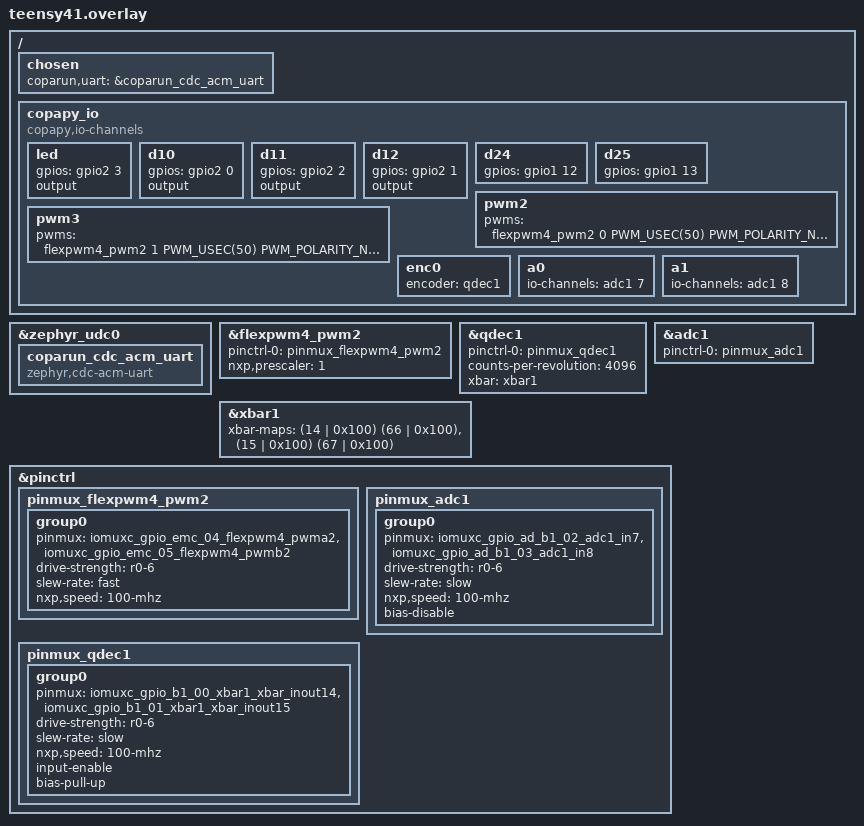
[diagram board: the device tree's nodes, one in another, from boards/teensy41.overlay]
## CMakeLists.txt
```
cmake_minimum_required(VERSION 3.20.0)

find_package(Zephyr REQUIRED HINTS $ENV{ZEPHYR_BASE})
project(coparun)

# Core of the runner, shared with the other runners
set(CORE_DIR ${CMAKE_CURRENT_SOURCE_DIR}/../../src/coparun)

target_sources(app PRIVATE
    src/main.c
    src/tasks.c
    src/io.c
    ${CORE_DIR}/runmem.c
    ${CORE_DIR}/tasks.c
    ${CORE_DIR}/mem_man.c
)
target_include_directories(app PRIVATE ${CORE_DIR})

if(CONFIG_COPARUN_LOGGING)
    target_compile_definitions(app PRIVATE ENABLE_LOGGING)
else()
    target_compile_definitions(app PRIVATE ENABLE_BASIC_LOGGING)
endif()
```

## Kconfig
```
menu "coparun"

config COPARUN_HEAP_SIZE
	int "Size of the heap for copapy programs in bytes"
	default 262144
	help
	  The heap holds the code and data memory of the copapy programs.

config COPARUN_HEAP_SECTION
	string "Linker section of the heap for copapy programs"
	default ".noinit.coparun_heap"
	help
	  Code is executed from the heap, it must be located in memory that is
	  not marked execute-never by the MPU. With CONFIG_ARM_MPU the main RAM
	  is execute-never on targets running from flash: either select the
	  section of a memory region that is not covered by an MPU region (name
	  of a devicetree node with zephyr,memory-region) or disable the MPU.

config COPARUN_MAX_FRAME_SIZE
	int "Maximum size of the command stream part of a frame in bytes"
	default 4096

config COPARUN_RX_RING_SIZE
	int "Size of the UART receive ring buffer in bytes"
	default 2048

config COPARUN_TX_RING_SIZE
	int "Size of the UART transmit ring buffer in bytes"
	default 1024

config COPARUN_TX_TIMEOUT_MS
	int "Time without progress after which output is dropped in ms"
	default 500
	help
	  Output is written blocking. If the host does not read it for this
	  time, the output is dropped until the host reads again.

config COPARUN_RX_TIMEOUT_MS
	int "Timeout for receiving the remaining bytes of a frame in ms"
	default 2000

config COPARUN_MAX_TASKS
	int "Maximum number of tasks for the real-time execution"
	default 8
	range 1 32

config COPARUN_TASK_PRIORITY
	int "Thread priority of the first (highest priority) task"
	default 1
	help
	  Task n runs with this priority + n. The main thread must have a
	  lower priority (higher number) than all tasks.

config COPARUN_MAX_TASK_LOAD
	int "Maximum CPU load of the tasks in percent"
	default 90
	range 10 100
	help
	  If the tasks use more CPU time, the tasks with the lowest priority
	  run with lower priority than the communication with the host until
	  the load is below the limit again (load shedding, see tasks.c).
	  100 disables the load shedding.

config COPARUN_LOAD_WINDOW_MS
	int "Time window of the load measurement in ms"
	default 100

config COPARUN_TASK_STACK_SIZE
	int "Stack size of each task thread in bytes"
	default 2048

config COPARUN_LOGGING
	bool "Log all commands of the command stream"
	help
	  Without this option only the return value of the program and the
	  data of READ_DATA commands are written to the console.

endmenu

source "Kconfig.zephyr"

# mps2/an500 is used for testing in qemu: its Cortex-M7 has an FPU, which is
# not declared by the SoC definition of Zephyr
config SOC_AN500
	select CPU_HAS_FPU
```

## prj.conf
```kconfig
# The stencils use the FPU with the hard float ABI
CONFIG_FPU=y
CONFIG_FPU_SHARING=y
CONFIG_FP_HARDABI=y

# Command streams are received over the console UART
CONFIG_SERIAL=y
CONFIG_UART_INTERRUPT_DRIVEN=y
CONFIG_RING_BUFFER=y
CONFIG_CRC=y
CONFIG_REBOOT=y

# Device I/O channels (io.c)
CONFIG_GPIO=y

# Programs run on the main thread (RUN_PROG, RUN_TASK, STEP_TASKS) and
# periodic tasks on threads with higher priority than the main thread
CONFIG_MAIN_STACK_SIZE=8192
CONFIG_MAIN_THREAD_PRIORITY=10
# Priorities below the main thread for degraded tasks (load shedding)
CONFIG_NUM_PREEMPT_PRIORITIES=24

# Tick of the periodic tasks: 100 us
CONFIG_SYS_CLOCK_TICKS_PER_SEC=10000

# CPU time of the task threads for the execution time measurement
CONFIG_THREAD_RUNTIME_STATS=y
```

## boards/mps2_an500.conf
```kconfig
# The heap is located in the main RAM, which is execute-never with MPU
CONFIG_ARM_MPU=n

CONFIG_COPARUN_HEAP_SIZE=1048576
```

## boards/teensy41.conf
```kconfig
# The MPU stays enabled (required by the USB driver). The main RAM (FlexRAM
# OCRAM, 256 KiB) is execute-never, the heap uses the complete 512 KiB OCRAM2
# instead, which is not covered by an MPU region.
CONFIG_COPARUN_HEAP_SECTION="OCRAM2"
CONFIG_COPARUN_HEAP_SIZE=524288

# Drivers of the I/O channels (see teensy41.overlay), the quadrature decoder
# is a sensor driver
CONFIG_PWM=y
CONFIG_SENSOR=y
CONFIG_ADC=y

# USB serial port of the runner
CONFIG_USB_DEVICE_STACK_NEXT=y
CONFIG_CDC_ACM_SERIAL_INITIALIZE_AT_BOOT=y

# USB processing must not delay the tasks: preemptible work queues with
# lower priority than the task threads (the default is cooperative)
CONFIG_UDC_WORKQUEUE_PRIORITY=9
CONFIG_SYSTEM_WORKQUEUE_PRIORITY=9
```

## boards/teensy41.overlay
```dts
/*
 * The runner communicates over USB (CDC ACM), the Zephyr console stays on
 * LPUART6 (Teensy pins 0 and 1).
 */

#include <zephyr/dt-bindings/gpio/gpio.h>
#include <zephyr/dt-bindings/pwm/pwm.h>

/ {
	chosen {
		coparun,uart = &coparun_cdc_acm_uart;
	};

	/* I/O channels for copapy (see dts/bindings/copapy,io-channels.yaml),
	 * named by Teensy pin numbers. Pins 0/1 are the console, 22/23 CAN. */
	copapy_io {
		compatible = "copapy,io-channels";

		led {
			gpios = <&gpio2 3 GPIO_ACTIVE_HIGH>;    /* pin 13, GPIO_B0_03 */
			output;
		};
		d10 {
			gpios = <&gpio2 0 GPIO_ACTIVE_HIGH>;    /* GPIO_B0_00 */
			output;
		};
		d11 {
			gpios = <&gpio2 2 GPIO_ACTIVE_HIGH>;    /* GPIO_B0_02 */
			output;
		};
		d12 {
			gpios = <&gpio2 1 GPIO_ACTIVE_HIGH>;    /* GPIO_B0_01 */
			output;
		};
		d24 {
			gpios = <&gpio1 12 (GPIO_ACTIVE_HIGH | GPIO_PULL_UP)>;  /* GPIO_AD_B0_12 */
		};
		d25 {
			gpios = <&gpio1 13 (GPIO_ACTIVE_HIGH | GPIO_PULL_UP)>;  /* GPIO_AD_B0_13 */
		};
		pwm2 {
			pwms = <&flexpwm4_pwm2 0 PWM_USEC(50) PWM_POLARITY_NORMAL>;  /* 20 kHz */
		};
		pwm3 {
			pwms = <&flexpwm4_pwm2 1 PWM_USEC(50) PWM_POLARITY_NORMAL>;
		};
		enc0 {
			encoder = <&qdec1>;                      /* phase A pin 8, B pin 7 */
		};
		a0 {
			io-channels = <&adc1 7>;                 /* pin 14 */
		};
		a1 {
			io-channels = <&adc1 8>;                 /* pin 15 */
		};
	};
};

&zephyr_udc0 {
	coparun_cdc_acm_uart: coparun_cdc_acm_uart {
		compatible = "zephyr,cdc-acm-uart";
	};
};

/* PWM pins 2 (A) and 3 (B): FlexPWM4 submodule 2 at full clock (150 MHz,
 * 7500 steps at 20 kHz) */
&flexpwm4_pwm2 {
	status = "okay";
	pinctrl-0 = <&pinmux_flexpwm4_pwm2>;
	pinctrl-names = "default";
	nxp,prescaler = <1>;
};

/* Quadrature decoder ENC1, inputs through the crossbar */
&qdec1 {
	status = "okay";
	pinctrl-0 = <&pinmux_qdec1>;
	pinctrl-names = "default";
	counts-per-revolution = <4096>;
	xbar = <&xbar1>;
};

&xbar1 {
	status = "okay";
	xbar-maps =
		/* kXBARA1_InputIomuxXbarInout14 -> kXBARA1_OutputEnc1PhaseAInput */
		<(14 | 0x100) (66 | 0x100)>,
		/* kXBARA1_InputIomuxXbarInout15 -> kXBARA1_OutputEnc1PhaseBInput */
		<(15 | 0x100) (67 | 0x100)>;
};

/* ADC1, its driver requires a pin configuration */
&adc1 {
	status = "okay";
	pinctrl-0 = <&pinmux_adc1>;
	pinctrl-names = "default";
};

&pinctrl {
	pinmux_flexpwm4_pwm2: pinmux_flexpwm4_pwm2 {
		group0 {
			pinmux = <&iomuxc_gpio_emc_04_flexpwm4_pwma2>,
				 <&iomuxc_gpio_emc_05_flexpwm4_pwmb2>;
			drive-strength = "r0-6";
			slew-rate = "fast";
			nxp,speed = "100-mhz";
		};
	};

	pinmux_adc1: pinmux_adc1 {
		group0 {
			pinmux = <&iomuxc_gpio_ad_b1_02_adc1_in7>,
				 <&iomuxc_gpio_ad_b1_03_adc1_in8>;
			drive-strength = "r0-6";
			slew-rate = "slow";
			nxp,speed = "100-mhz";
			bias-disable;
		};
	};

	pinmux_qdec1: pinmux_qdec1 {
		group0 {
			pinmux = <&iomuxc_gpio_b1_00_xbar1_xbar_inout14>,
				 <&iomuxc_gpio_b1_01_xbar1_xbar_inout15>;
			drive-strength = "r0-6";
			slew-rate = "slow";
			nxp,speed = "100-mhz";
			input-enable;
			bias-pull-up;
		};
	};
};
```

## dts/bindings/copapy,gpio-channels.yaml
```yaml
description: |
  GPIO channels of the copapy runner. Each child node is a channel, named by
  the node name (e.g. "led"). Copapy values are bound to the channels by name
  with SerialTarget.bind.

    copapy_gpio {
        compatible = "copapy,gpio-channels";
        led {
            gpios = <&gpio2 3 GPIO_ACTIVE_HIGH>;
            output;
        };
        button {
            gpios = <&gpio1 12 (GPIO_ACTIVE_LOW | GPIO_PULL_UP)>;
        };
    };

compatible: "copapy,gpio-channels"

child-binding:
  description: GPIO channel
  properties:
    gpios:
      type: phandle-array
      required: true
      description: Pin, active level and pull resistor of the channel
    output:
      type: boolean
      description: Output channel, otherwise input channel
```

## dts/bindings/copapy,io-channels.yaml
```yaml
description: |
  I/O channels of the copapy runner. Each child node is a channel, named by
  the node name. Copapy values are bound to the channels by name with
  SerialTarget.bind. The kind of a channel follows from its property:

    copapy_io {
        compatible = "copapy,io-channels";
        led {
            gpios = <&gpio2 3 GPIO_ACTIVE_HIGH>;
            output;
        };
        motor {
            pwms = <&flexpwm4_pwm2 0 PWM_USEC(50) PWM_POLARITY_NORMAL>;
        };
        enc0 {
            encoder = <&qdec1>;
        };
        a0 {
            io-channels = <&adc1 7>;
        };
    };

compatible: "copapy,io-channels"

child-binding:
  description: I/O channel
  properties:
    gpios:
      type: phandle-array
      description: GPIO pin, active level and pull resistor
    output:
      type: boolean
      description: GPIO output, otherwise GPIO input
    pwms:
      type: phandle-array
      description: PWM output with period and polarity, the duty cycle is written
    encoder:
      type: phandle
      description: Quadrature decoder, the position count is read
    io-channels:
      type: phandle-array
      description: ADC and its input, the raw conversion result is read
```

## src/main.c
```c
/*
 * file: main.c
 * Description: Runner for Zephyr targets. Command streams are received
 * framed over a UART, the output of the runner is sent in binary messages
 * (protocol.h) over the same UART. The UART is selected by the chosen
 * devicetree node "coparun,uart" (e.g. a USB CDC ACM device), by default it
 * is the console. The protocol is described in docs/source/runner_transfer.md.
 *
 * Stream frame (integers little endian):
 *   4 bytes  magic "CPY1"
 *   uint32   length n of the following part of the command stream in bytes,
 *            at most CONFIG_COPARUN_MAX_FRAME_SIZE
 *   n bytes  part of the command stream
 *   uint32   CRC-32 (IEEE 802.3, as zlib.crc32) of the n bytes
 *
 * A command stream can be split at any position into several frames. Each
 * frame is answered with the output of the runner followed by a MSG_DONE
 * message with the state flag of the parser (0: command stream is continued
 * by the next frame, 1: END_COM reached, 2: DUMP_CODE reached, negative:
 * error), or by MSG_ERROR if the frame was not valid. A frame is processed
 * only after its checksum was verified, a frame answered with ERR_TIMEOUT or
 * ERR_CHECKSUM can be sent again. The next frame must not be sent before the
 * answer was received. The run-time memory state is kept between frames and
 * command streams.
 *
 * Control frame:
 *   4 bytes  magic "CPYC"
 *   uint32   0: abort the current command stream, the next frame starts a
 *               new one
 *            1: reset the device
 *            2: enter the bootloader, Teensy only
 *            answered by MSG_CONTROL with the code before it is executed
 *
 * Bytes in front of a magic are ignored. After start up MSG_READY is sent.
 * Text written to stdout is sent in MSG_TEXT messages, the data of READ_MEM
 * in MSG_DATA messages.
 *
 * Periodic tasks are run in real time after START_TASKS (see tasks.c), the
 * communication with the host continues meanwhile.
 */

#include <stdio.h>
#include <stdint.h>
#include <string.h>
#include <zephyr/kernel.h>
#include <zephyr/device.h>
#include <zephyr/drivers/uart.h>
#include <zephyr/sys/byteorder.h>
#include <zephyr/sys/crc.h>
#include <zephyr/sys/libc-hooks.h>
#include <zephyr/sys/printk.h>
#include <zephyr/sys/reboot.h>
#include <zephyr/sys/ring_buffer.h>
#include "runmem.h"
#include "tasks.h"
#include "protocol.h"

#define RX_TIMEOUT K_MSEC(CONFIG_COPARUN_RX_TIMEOUT_MS)

/* UART of the runner: chosen node "coparun,uart", by default the console */
#if DT_HAS_CHOSEN(coparun_uart)
#define COPARUN_UART_NODE DT_CHOSEN(coparun_uart)
#else
#define COPARUN_UART_NODE DT_CHOSEN(zephyr_console)
#endif

static const struct device *const uart_dev = DEVICE_DT_GET(COPARUN_UART_NODE);

static const uint8_t frame_magic[3] = {'C', 'P', 'Y'};
#define FRAME_TYPE_STREAM  '1'
#define FRAME_TYPE_CONTROL 'C'

#define CONTROL_ABORT      0
#define CONTROL_RESET      1
#define CONTROL_BOOTLOADER 2

RING_BUF_DECLARE(rx_ring, CONFIG_COPARUN_RX_RING_SIZE);
static K_SEM_DEFINE(rx_sem, 0, 1);
static volatile bool rx_paused;

RING_BUF_DECLARE(tx_ring, CONFIG_COPARUN_TX_RING_SIZE);
static K_SEM_DEFINE(tx_sem, 0, 1);
static volatile bool tx_stalled;

/* Command stream of a frame, preceded by the bytes of an incomplete command
   of the previous frame (at most 19 bytes) */
#define MAX_PENDING 20
static uint8_t frame_buffer[MAX_PENDING + CONFIG_COPARUN_MAX_FRAME_SIZE];
static uint32_t pending;

/* Text output, sent at the end of a line, if the buffer is full or before
   the next message */
static uint8_t text_buffer[MSG_MAX_PAYLOAD];
static uint32_t text_len;

static runmem_t targ;

static void uart_isr(const struct device *dev, void *user_data) {
    ARG_UNUSED(user_data);

    while (uart_irq_update(dev) && uart_irq_is_pending(dev)) {
        if (uart_irq_rx_ready(dev)) {
            uint8_t *data;
            uint32_t space = ring_buf_put_claim(&rx_ring, &data, CONFIG_COPARUN_RX_RING_SIZE);

            if (space) {
                int len = uart_fifo_read(dev, data, (int)space);

                ring_buf_put_finish(&rx_ring, len > 0 ? (uint32_t)len : 0);
            } else {
                /* Receiving is paused until the main thread has read data:
                   back pressure to the host if the driver supports it (USB) */
                uart_irq_rx_disable(dev);
                rx_paused = true;
            }
            k_sem_give(&rx_sem);
        }
        if (uart_irq_tx_ready(dev)) {
            uint8_t *data;
            uint32_t len = ring_buf_get_claim(&tx_ring, &data, CONFIG_COPARUN_TX_RING_SIZE);

            if (len) {
                int sent = uart_fifo_fill(dev, data, (int)len);

                ring_buf_get_finish(&tx_ring, sent > 0 ? (uint32_t)sent : 0);
                tx_stalled = false;
            } else {
                uart_irq_tx_disable(dev);
            }
            k_sem_give(&tx_sem);
        }
    }
}

/* Output: written without loss as long as the host reads it. The poll mode
   of a USB CDC ACM device drops characters if its buffer is full. */
static void tx_put(const uint8_t *data, uint32_t len) {
    while (len) {
        uint32_t n = ring_buf_put(&tx_ring, data, len);

        data += n;
        len -= n;
        if (!len) break;
        /* Output is dropped if the host does not read it */
        if (tx_stalled) return;
        uart_irq_tx_enable(uart_dev);
        if (k_sem_take(&tx_sem, K_MSEC(CONFIG_COPARUN_TX_TIMEOUT_MS)) != 0) {
            tx_stalled = true;
            return;
        }
    }
}

static void put_message(uint8_t type, const void *payload, uint32_t len) {
    uint8_t header[4] = {MSG_SYNC, type, (uint8_t)len, (uint8_t)(type ^ len ^ 0xFF)};
    uint8_t crc[2];

    sys_put_le16(crc16_itu_t(crc16_itu_t(0, header + 1, 3), payload, len), crc);
    tx_put(header, sizeof(header));
    tx_put(payload, len);
    tx_put(crc, sizeof(crc));
    uart_irq_tx_enable(uart_dev);
}

static void text_flush(void) {
    if (text_len) {
        put_message(MSG_TEXT, text_buffer, text_len);
        text_len = 0;
    }
}

void send_message(uint8_t type, const void *payload, uint32_t len) {
    text_flush();
    put_message(type, payload, len);
}

static void send_byte(uint8_t type, uint8_t value) {
    send_message(type, &value, 1);
}

static int stdout_write(int c) {
    text_buffer[text_len++] = (uint8_t)c;
    if (c == '\n' || text_len == sizeof(text_buffer)) text_flush();
    return c;
}

void runmem_write_data(const uint8_t *data, uint32_t size) {
    while (size) {
        uint32_t len = size < MSG_MAX_PAYLOAD ? size : MSG_MAX_PAYLOAD;

        send_message(MSG_DATA, data, len);
        data += len;
        size -= len;
    }
}

/* Reads len bytes, returns 0 if no data was received for the time of timeout */
static int read_bytes(uint8_t *dest, uint32_t len, k_timeout_t timeout) {
    while (len) {
        uint32_t n = ring_buf_get(&rx_ring, dest, len);

        dest += n;
        len -= n;
        if (rx_paused) {
            /* Space in the ring buffer again */
            rx_paused = false;
            uart_irq_rx_enable(uart_dev);
        }
        if (!n && k_sem_take(&rx_sem, timeout) != 0) return 0;
    }
    return 1;
}

/* Waits for the magic of a frame, returns its last character (frame type) */
static uint8_t wait_for_magic(void) {
    uint32_t matched = 0;
    uint8_t c;

    for (;;) {
        read_bytes(&c, 1, K_FOREVER);
        if (matched == sizeof(frame_magic)) {
            if (c == FRAME_TYPE_STREAM || c == FRAME_TYPE_CONTROL) return c;
            matched = 0;
        }
        if (c == frame_magic[matched]) {
            matched++;
        } else {
            matched = (c == frame_magic[0]);
        }
    }
}

/* Receives the remaining stream frame after the magic and appends the
   command stream to frame_buffer, returns ERR_* on failure, else 0 */
static uint8_t receive_frame(uint32_t *len) {
    uint8_t word[4];

    if (!read_bytes(word, sizeof(word), RX_TIMEOUT)) return ERR_TIMEOUT;
    *len = sys_get_le32(word);

    if (*len > CONFIG_COPARUN_MAX_FRAME_SIZE) return ERR_FRAME_TOO_LARGE;
    if (!read_bytes(frame_buffer + pending, *len, RX_TIMEOUT) ||
        !read_bytes(word, sizeof(word), RX_TIMEOUT)) return ERR_TIMEOUT;
    if (sys_get_le32(word) != crc32_ieee(frame_buffer + pending, *len)) return ERR_CHECKSUM;
    return 0;
}

static void process_stream_frame(void) {
    uint32_t len;
    uint8_t error = receive_frame(&len);

    if (error) {
        send_byte(MSG_ERROR, error);
        return;
    }

    uint32_t consumed = (uint32_t)parse_commands(&targ, frame_buffer, pending + len);

    if (targ.state_flag == STATE_FLAG_NONE) {
        /* Keep the bytes of an incomplete command for the next frame */
        pending += len - consumed;
        memmove(frame_buffer, frame_buffer + consumed, pending);
    } else {
        /* End of the command stream or parser out of sync */
        pending = 0;
        targ.rx_state = RX_STATE_IDLE;
    }
    fflush(stdout);
    send_byte(MSG_DONE, (uint8_t)(int8_t)targ.state_flag);
}

static void process_control_frame(void) {
    uint8_t word[4];

    if (!read_bytes(word, sizeof(word), RX_TIMEOUT)) {
        send_byte(MSG_ERROR, ERR_TIMEOUT);
        return;
    }

    switch (sys_get_le32(word)) {
        case CONTROL_ABORT:
            pending = 0;
            targ.rx_state = RX_STATE_IDLE;
            send_byte(MSG_CONTROL, CONTROL_ABORT);
            break;

        case CONTROL_RESET:
            send_byte(MSG_CONTROL, CONTROL_RESET);
            k_msleep(100);  /* Let the output drain */
            sys_reboot(SYS_REBOOT_COLD);
            break;

#ifdef CONFIG_BOARD_TEENSY41
        case CONTROL_BOOTLOADER:
            send_byte(MSG_CONTROL, CONTROL_BOOTLOADER);
            k_msleep(100);
            /* Request of the bootloader chip of the Teensy (HalfKay) */
            __asm__ volatile("bkpt #251");
            break;
#endif

        default:
            send_byte(MSG_ERROR, ERR_CONTROL_CODE);
            break;
    }
}

int main(void) {
    if (!device_is_ready(uart_dev)) {
        printk("coparun: UART not ready\n");
        return 0;
    }

    uart_irq_callback_set(uart_dev, uart_isr);
    uart_irq_rx_enable(uart_dev);
    __stdout_hook_install(stdout_write);

    send_byte(MSG_READY, PROTOCOL_VERSION);

    for (;;) {
        if (wait_for_magic() == FRAME_TYPE_STREAM) {
            process_stream_frame();
        } else {
            process_control_frame();
        }
    }
    return 0;
}
```

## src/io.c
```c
/*
 * file: io.c
 * Description: Device I/O channels of the runner. The channels are child
 * nodes of the devicetree node "copapy,io-channels" (see
 * dts/bindings/copapy,io-channels.yaml), numbered in the order of
 * definition. The kind of a channel follows from its property:
 *   gpios        gpio_in / gpio_out  int32, 0: inactive, else active
 *   pwms         pwm_out             float, duty cycle 0..1
 *   encoder      encoder_in          int32, position count
 *   io-channels  adc_in              int32, raw conversion result
 *
 * Channels are read and written in the interrupt of the task tick (see
 * runmem.h). The Zephyr drivers initialize the peripherals, PWM, encoder
 * and ADC are accessed by registers since their driver functions block.
 */

#include <stdio.h>
#include <string.h>
#include <zephyr/kernel.h>
#include <zephyr/init.h>
#include <zephyr/drivers/gpio.h>
#include <zephyr/drivers/pwm.h>
#include <zephyr/sys/byteorder.h>
#include "runmem.h"
#include "tasks.h"
#include "protocol.h"

enum kind {
    GPIO_IN = IO_KIND_GPIO_IN,
    GPIO_OUT = IO_KIND_GPIO_OUT,
    PWM_OUT = IO_KIND_PWM_OUT,
    ENCODER_IN = IO_KIND_ENCODER_IN,
    ADC_IN = IO_KIND_ADC_IN
};

struct channel {
    const char *name;
    enum kind kind;
    struct gpio_dt_spec gpio;    /* GPIO */
    struct pwm_dt_spec pwm;      /* PWM */
    const struct device *dev;    /* encoder, ADC */
    uintptr_t base;              /* registers of the PWM, encoder or ADC */
    uint32_t index;              /* PWM submodule, ADC input */
};

#define IO_NODE DT_COMPAT_GET_ANY_STATUS_OKAY(copapy_io_channels)

#define GPIO_CHANNEL(node) \
    .kind = DT_PROP(node, output) ? GPIO_OUT : GPIO_IN, \
    .gpio = GPIO_DT_SPEC_GET(node, gpios),

#define PWM_CHANNEL(node) \
    .kind = PWM_OUT, \
    .pwm = PWM_DT_SPEC_GET(node), \
    .base = DT_REG_ADDR(DT_PARENT(DT_PWMS_CTLR(node))), \
    .index = DT_PROP(DT_PWMS_CTLR(node), index),

#define ENCODER_CHANNEL(node) \
    .kind = ENCODER_IN, \
    .dev = DEVICE_DT_GET(DT_PHANDLE(node, encoder)), \
    .base = DT_REG_ADDR(DT_PHANDLE(node, encoder)),

#define ADC_CHANNEL(node) \
    .kind = ADC_IN, \
    .dev = DEVICE_DT_GET(DT_IO_CHANNELS_CTLR(node)), \
    .base = DT_REG_ADDR(DT_IO_CHANNELS_CTLR(node)), \
    .index = DT_IO_CHANNELS_INPUT(node),

#define CHANNEL(node) {                                                     \
    .name = DT_NODE_FULL_NAME(node),                                        \
    COND_CODE_1(DT_NODE_HAS_PROP(node, gpios), (GPIO_CHANNEL(node)),        \
    (COND_CODE_1(DT_NODE_HAS_PROP(node, pwms), (PWM_CHANNEL(node)),         \
    (COND_CODE_1(DT_NODE_HAS_PROP(node, encoder), (ENCODER_CHANNEL(node)),  \
    (ADC_CHANNEL(node)))))))                                                \
},

#if DT_NODE_EXISTS(IO_NODE)
static const struct channel channels[] = {DT_FOREACH_CHILD(IO_NODE, CHANNEL)};
#else
static const struct channel channels[] = {};
#endif

#define CHANNEL_COUNT ARRAY_SIZE(channels)

static bool channel_ready[CHANNEL_COUNT + 1];

/* Register access for NXP i.MX RT (FlexPWM, ENC, 12 bit ADC) */
#ifdef CONFIG_HAS_MCUX
#include <fsl_adc.h>
#include <fsl_enc.h>
#include <fsl_pwm.h>

static void pwm_write_pulse(const struct channel *ch, uint32_t pulse) {
    PWM_Type *base = (PWM_Type *)ch->base;

    /* Edge aligned PWM (set up by the driver): output A ends at VAL3, B at VAL5 */
    if (ch->pwm.channel == 0) {
        base->SM[ch->index].VAL3 = (uint16_t)pulse;
    } else {
        base->SM[ch->index].VAL5 = (uint16_t)pulse;
    }
    PWM_SetPwmLdok(base, (uint8_t)(1U << ch->index), true);
}

static int32_t encoder_read(const struct channel *ch) {
    return (int32_t)ENC_GetPositionValue((ENC_Type *)ch->base);
}

static int32_t adc_read(const struct channel *ch) {
    ADC_Type *base = (ADC_Type *)ch->base;
    adc_channel_config_t config = {.channelNumber = ch->index};

    /* Conversion takes about 1-2 us, a missing result is reported as -1 */
    ADC_SetChannelConfig(base, 0, &config);
    for (int i = 0; i < 10000; i++) {
        if (ADC_GetChannelStatusFlags(base, 0)) return (int32_t)ADC_GetChannelConversionValue(base, 0);
    }
    return -1;
}
#else
static void pwm_write_pulse(const struct channel *ch, uint32_t pulse) { ARG_UNUSED(ch); ARG_UNUSED(pulse); }
static int32_t encoder_read(const struct channel *ch) { ARG_UNUSED(ch); return 0; }
static int32_t adc_read(const struct channel *ch) { ARG_UNUSED(ch); return 0; }
#endif

/* PWM period in timer cycles, set at start up */
static uint32_t pwm_period_cycles[CHANNEL_COUNT + 1];

static bool init_channel(uint32_t i) {
    const struct channel *ch = &channels[i];
    uint64_t cycles_per_sec;

    switch (ch->kind) {
        case GPIO_IN:
            return gpio_is_ready_dt(&ch->gpio) && gpio_pin_configure_dt(&ch->gpio, GPIO_INPUT) == 0;
        case GPIO_OUT:
            return gpio_is_ready_dt(&ch->gpio) && gpio_pin_configure_dt(&ch->gpio, GPIO_OUTPUT_INACTIVE) == 0;
        case PWM_OUT:
            if (!pwm_is_ready_dt(&ch->pwm) || pwm_set_pulse_dt(&ch->pwm, 0) != 0 ||
                pwm_get_cycles_per_sec(ch->pwm.dev, ch->pwm.channel, &cycles_per_sec) != 0) return false;
            pwm_period_cycles[i] = (uint32_t)(ch->pwm.period * cycles_per_sec / NSEC_PER_SEC);
            return true;
        default:
            return device_is_ready(ch->dev);
    }
}

static int io_init(void) {
    for (uint32_t i = 0; i < CHANNEL_COUNT; i++) {
        channel_ready[i] = init_channel(i);
    }
    return 0;
}

SYS_INIT(io_init, APPLICATION, CONFIG_APPLICATION_INIT_PRIORITY);

void runmem_io_read(uint32_t channel, uint8_t *value) {
    int32_t result = 0;

    if (channel < CHANNEL_COUNT && channel_ready[channel]) {
        const struct channel *ch = &channels[channel];

        switch (ch->kind) {
            case GPIO_IN:
            case GPIO_OUT:  /* level of the output */
                result = gpio_pin_get_dt(&ch->gpio) > 0;
                break;
            case ENCODER_IN:
                result = encoder_read(ch);
                break;
            case ADC_IN:
                result = adc_read(ch);
                break;
            default:
                break;
        }
    }
    memcpy(value, &result, sizeof(result));
}

void runmem_io_write(uint32_t channel, const uint8_t *value) {
    if (channel >= CHANNEL_COUNT || !channel_ready[channel]) return;
    const struct channel *ch = &channels[channel];

    if (ch->kind == GPIO_OUT) {
        int32_t level;

        memcpy(&level, value, sizeof(level));
        gpio_pin_set_dt(&ch->gpio, level != 0);
    } else if (ch->kind == PWM_OUT) {
        float duty;

        memcpy(&duty, value, sizeof(duty));
        if (!(duty > 0.0f)) duty = 0.0f;  /* also NaN */
        if (duty > 1.0f) duty = 1.0f;
        pwm_write_pulse(ch, (uint32_t)(duty * (float)pwm_period_cycles[channel] + 0.5f));
    }
}

void runmem_io_list(void) {
    for (uint32_t i = 0; i < CHANNEL_COUNT; i++) {
        if (!channel_ready[i]) continue;
        /* uint16 channel, uint8 kind, name */
        uint8_t payload[MSG_MAX_PAYLOAD];
        uint32_t len = (uint32_t)strlen(channels[i].name);

        if (len > sizeof(payload) - 3) len = sizeof(payload) - 3;
        sys_put_le16((uint16_t)i, payload);
        payload[2] = (uint8_t)channels[i].kind;
        memcpy(payload + 3, channels[i].name, len);
        send_message(MSG_IO, payload, len + 3);
    }
}
```

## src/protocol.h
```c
/*
 * file: protocol.h
 * Description: Messages from the runner to the host (backchannel), see
 * docs/source/runner_transfer.md. All output of the runner, including the
 * text written to stdout, is sent in messages (integers little endian):
 *
 *   uint8   sync byte MSG_SYNC (never part of ASCII text)
 *   uint8   message type MSG_*
 *   uint8   length n of the payload (0..255)
 *   uint8   header check: type ^ length ^ 0xFF
 *   n bytes payload
 *   uint16  CRC-16/XMODEM of type, length, header check and payload
 *
 * Messages are only sent by the main thread.
 */

#ifndef PROTOCOL_H
#define PROTOCOL_H

#include <stdint.h>

#define MSG_SYNC        0xCA
#define MSG_MAX_PAYLOAD 255
#define PROTOCOL_VERSION 1

/* Message types and their payload */
#define MSG_READY    0x01  /* uint8 protocol version: runner started */
#define MSG_DONE     0x02  /* int8 state flag of the parser: stream frame processed */
#define MSG_ERROR    0x03  /* uint8 ERR_*: frame not processed */
#define MSG_CONTROL  0x04  /* uint8 control code: control frame executed */
#define MSG_DATA     0x05  /* data memory read by READ_MEM (part) */
#define MSG_TEXT     0x06  /* text output of the runner (part, lines end with '\n') */
#define MSG_IO       0x07  /* uint16 channel, uint8 IO_KIND_*, name: I/O channel (LIST_IO) */

/* Error codes of MSG_ERROR */
#define ERR_TIMEOUT         1  /* frame incomplete, can be sent again */
#define ERR_CHECKSUM        2  /* CRC of the frame wrong, can be sent again */
#define ERR_FRAME_TOO_LARGE 3
#define ERR_CONTROL_CODE    4  /* unknown control code */

/* I/O channel kinds of MSG_IO */
#define IO_KIND_GPIO_IN    0
#define IO_KIND_GPIO_OUT   1
#define IO_KIND_PWM_OUT    2
#define IO_KIND_ENCODER_IN 3
#define IO_KIND_ADC_IN     4

/* Sends a message with a payload of at most MSG_MAX_PAYLOAD bytes; pending
   text output is sent before */
void send_message(uint8_t type, const void *payload, uint32_t len);

#endif /* PROTOCOL_H */
```

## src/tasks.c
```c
/*
 * file: tasks.c
 * Description: Real-time execution of the periodic tasks of a copapy
 * program on Zephyr. A timer with the period of the tick publishes the
 * outputs and latches the inputs of the tasks in its interrupt (see
 * tasks_publish and tasks_latch in src/coparun/tasks.c). The released jobs run on one
 * thread per task with preemptive priorities in the order of the task table
 * (first task: highest priority). The main thread (communication with the
 * host) has a lower priority than all tasks.
 *
 * Load shedding: a supervisor thread with the highest priority measures the
 * CPU load of the task threads in windows of CONFIG_COPARUN_LOAD_WINDOW_MS.
 * If the load exceeds CONFIG_COPARUN_MAX_TASK_LOAD percent, the tasks with
 * the lowest priority are degraded until the load of the remaining tasks is
 * below the limit: they run with lower priority than the main thread, i.e.
 * the host communication is served first and their releases are skipped
 * (overruns) as long as their jobs are not finished. A degraded task is
 * restored (one per window, highest priority first) if its estimated load
 * (mean CPU time per job / period) fits below the limit.
 */

#include <zephyr/kernel.h>
#include "runmem.h"
#include "tasks.h"

#define MAX_TASKS CONFIG_COPARUN_MAX_TASKS
#define LOAD_LIMIT CONFIG_COPARUN_MAX_TASK_LOAD  /* percent */
#define LOAD_HYSTERESIS 5                         /* percent */
#define SUPERVISOR_PRIORITY (CONFIG_COPARUN_TASK_PRIORITY - 1)
#define DEGRADED_PRIORITY (CONFIG_MAIN_THREAD_PRIORITY + 1)

BUILD_ASSERT(MAX_TASKS <= 32, "at most 32 tasks are supported by tasks_latch");
BUILD_ASSERT(CONFIG_COPARUN_TASK_PRIORITY >= 1, "the supervisor thread needs a higher priority than the tasks");
BUILD_ASSERT(CONFIG_COPARUN_TASK_PRIORITY + MAX_TASKS <= CONFIG_MAIN_THREAD_PRIORITY,
             "the main thread must have a lower priority than the task threads");
BUILD_ASSERT(DEGRADED_PRIORITY + MAX_TASKS <= K_LOWEST_APPLICATION_THREAD_PRIO,
             "CONFIG_NUM_PREEMPT_PRIORITIES too small for degraded tasks");

K_THREAD_STACK_ARRAY_DEFINE(task_stacks, MAX_TASKS, CONFIG_COPARUN_TASK_STACK_SIZE);
static struct k_thread task_threads[MAX_TASKS];
static struct k_sem task_sems[MAX_TASKS];
static bool threads_created;
static runmem_t *task_context;

/* Load measurement */
static K_SEM_DEFINE(supervisor_sem, 0, 1);
static uint32_t window_ticks;  /* 0: load shedding disabled */
static uint32_t tick_count;
static uint32_t tick_ns;
static uint32_t window_start;
static uint64_t window_cycles[MAX_TASKS];

static void tick_handler(struct k_timer *timer) {
    ARG_UNUSED(timer);

    tasks_publish(task_context);
    uint32_t released = tasks_latch(task_context);

    for (uint32_t i = 0; i < MAX_TASKS; i++) {
        if (released & (1u << i)) k_sem_give(&task_sems[i]);
    }

    if (window_ticks && ++tick_count >= window_ticks) {
        tick_count = 0;
        k_sem_give(&supervisor_sem);
    }
}

static K_TIMER_DEFINE(tick_timer, tick_handler, NULL);

static void task_thread(void *p1, void *p2, void *p3) {
    uint32_t index = (uint32_t)(uintptr_t)p1;

    ARG_UNUSED(p2);
    ARG_UNUSED(p3);

    for (;;) {
        k_sem_take(&task_sems[index], K_FOREVER);
        task_job(task_context, index);
    }
}

static uint64_t thread_cycles(uint32_t index) {
    k_thread_runtime_stats_t stats;

    k_thread_runtime_stats_get(&task_threads[index], &stats);
    return stats.execution_cycles;
}

static void set_degraded(task_t *task, uint32_t index, bool degraded) {
    task->degraded = degraded;
    if (degraded) task->degradations++;
    k_thread_priority_set(&task_threads[index], (degraded ? DEGRADED_PRIORITY : CONFIG_COPARUN_TASK_PRIORITY) + (int)index);
}

/* Estimated load of a task in percent: mean CPU time of its jobs per period */
static uint32_t estimated_load(const task_t *task) {
    uint64_t sum = (uint64_t)task->exec_sum_hi << 32 | task->exec_sum_lo;

    if (!task->runs) return 0;
    return (uint32_t)(sum * 100 / task->runs / ((uint64_t)task->period * tick_ns));
}

static void supervisor_thread(void *p1, void *p2, void *p3) {
    ARG_UNUSED(p1);
    ARG_UNUSED(p2);
    ARG_UNUSED(p3);

    for (;;) {
        k_sem_take(&supervisor_sem, K_FOREVER);

        runmem_t *context = task_context;
        if (!context->running) continue;

        uint32_t now = k_cycle_get_32();
        uint64_t window = now - window_start;
        uint32_t count = MIN(context->task_count, MAX_TASKS);
        uint32_t loads[MAX_TASKS];
        uint32_t load = 0;  /* percent, tasks that are not degraded */

        window_start = now;
        for (uint32_t i = 0; i < count; i++) {
            uint64_t cycles = thread_cycles(i);

            loads[i] = window ? (uint32_t)((cycles - window_cycles[i]) * 100 / window) : 0;
            window_cycles[i] = cycles;
            if (!context->tasks[i].degraded) load += loads[i];
        }

        if (load > LOAD_LIMIT) {
            /* Degrade tasks, lowest priority first, until the load is below the limit */
            for (uint32_t i = count; i-- > 0 && load > LOAD_LIMIT;) {
                task_t *task = &context->tasks[i];

                if (!task->period || task->degraded) continue;
                set_degraded(task, i, true);
                load -= MIN(load, loads[i]);
            }
        } else {
            /* Restore the degraded task with the highest priority if it fits */
            for (uint32_t i = 0; i < count; i++) {
                task_t *task = &context->tasks[i];

                if (!task->degraded) continue;
                if (load + estimated_load(task) + LOAD_HYSTERESIS <= LOAD_LIMIT) set_degraded(task, i, false);
                break;
            }
        }
    }
}

K_THREAD_STACK_DEFINE(supervisor_stack, 1024);
static struct k_thread supervisor;

int runmem_start(runmem_t *context, uint32_t tick_us) {
    if (context->task_count > MAX_TASKS) return 0;

    if (!threads_created) {
        for (uint32_t i = 0; i < MAX_TASKS; i++) {
            k_sem_init(&task_sems[i], 0, 1);
            k_thread_create(&task_threads[i], task_stacks[i], K_THREAD_STACK_SIZEOF(task_stacks[i]),
                            task_thread, (void *)(uintptr_t)i, NULL, NULL,
                            CONFIG_COPARUN_TASK_PRIORITY + (int)i, K_FP_REGS, K_NO_WAIT);
        }
        k_thread_create(&supervisor, supervisor_stack, K_THREAD_STACK_SIZEOF(supervisor_stack),
                        supervisor_thread, NULL, NULL, NULL, SUPERVISOR_PRIORITY, 0, K_NO_WAIT);
        threads_created = true;
    }

    task_context = context;
    for (uint32_t i = 0; i < context->task_count; i++) {
        set_degraded(&context->tasks[i], i, false);
        window_cycles[i] = thread_cycles(i);
    }
    tick_ns = tick_us * 1000u;
    tick_count = 0;
    window_ticks = LOAD_LIMIT < 100 ? CONFIG_COPARUN_LOAD_WINDOW_MS * 1000u / tick_us : 0;
    window_start = k_cycle_get_32();

    context->running = 1;
    k_timer_start(&tick_timer, K_NO_WAIT, K_USEC(tick_us));
    return 1;
}

/* Execution time measurement: hardware cycle counter of the system clock
   (CPU clock on Cortex-M with SysTick), CPU time of the threads by the
   runtime statistics of the kernel (time of interrupts during a job is
   counted for the job) */
uint32_t runmem_timestamp(void) {
    return k_cycle_get_32();
}

uint32_t runmem_cpu_time(void) {
    k_thread_runtime_stats_t stats;

    k_thread_runtime_stats_get(k_current_get(), &stats);
    return (uint32_t)stats.execution_cycles;
}

uint32_t runmem_to_ns(uint32_t delta) {
    return (uint32_t)k_cyc_to_ns_floor64(delta);
}

void runmem_stop(runmem_t *context) {
    if (!context->running) return;

    k_timer_stop(&tick_timer);
    context->running = 0;

    /* Wait for the released jobs (degraded tasks run while the main thread sleeps) */
    for (uint32_t i = 0; i < context->task_count; i++) {
        while (context->tasks[i].busy) k_msleep(1);
    }
}
```
